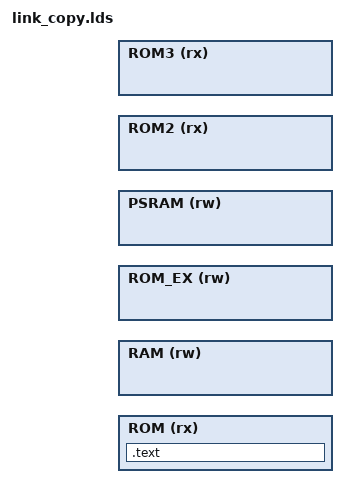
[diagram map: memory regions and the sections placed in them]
__ROM_BASE = ((0x12000000));
__ROM_SIZE = ((0x00008000));
__RAM_BASE = (0x20000000);
__RAM_SIZE = (0x0007FC00);
__STACK_SIZE = 0x00002000;
__HEAP_SIZE = 0x00000C00;
__ROM_EX_BASE = (0x2007FC00);
__ROM_EX_SIZE = (0x00000000);
__PSRAM_BASE = (0x60000000);
__PSRAM_SIZE = (0x00800000);
__ROM2_BASE = (((0x12000000)));
__ROM2_SIZE = (4096*1024);
__ROM3_BASE = (((((((0x12000000)))) + ((4096*1024)) - 1)) + 1);
__ROM3_SIZE = (4096*3*1024);
MEMORY
{
    ROM (rx) : ORIGIN = __ROM_BASE, LENGTH = __ROM_SIZE
    RAM (rw) : ORIGIN = __RAM_BASE, LENGTH = __RAM_SIZE
    ROM_EX(rw):ORIGIN = __ROM_EX_BASE, LENGTH = __ROM_EX_SIZE
    PSRAM(rw): ORIGIN = __PSRAM_BASE, LENGTH = __PSRAM_SIZE
    ROM2 (rx): ORIGIN = __ROM2_BASE, LENGTH = __ROM2_SIZE
    ROM3 (rx): ORIGIN = __ROM3_BASE, LENGTH = __ROM3_SIZE
}
ENTRY(Reset_Handler)
SECTIONS
{
  .text :
  {
    KEEP(*ftab.o(.text* .rodata*))
  } > ROM
}
